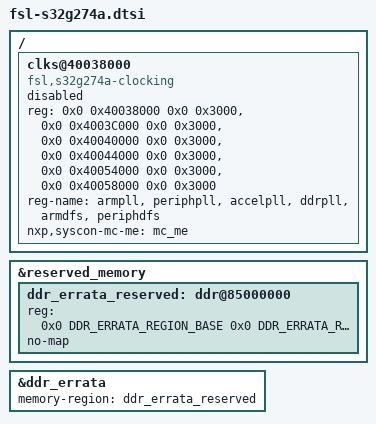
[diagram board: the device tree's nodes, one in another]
// SPDX-License-Identifier: GPL-2.0-or-later
/*
 * Device Tree file for S32G274ARDB Board.
 *
 * Copyright 2021-2022 NXP
 *
 */

#include <dt-bindings/ddr-errata/s32-ddr-errata.h>
#include "fsl-s32g.dtsi"

/ {
	clks@40038000 {
		compatible = "fsl,s32g274a-clocking";
		reg = <0x0 0x40038000 0x0 0x3000>,
		      <0x0 0x4003C000 0x0 0x3000>,
		      <0x0 0x40040000 0x0 0x3000>,
		      <0x0 0x40044000 0x0 0x3000>,
		      <0x0 0x40054000 0x0 0x3000>,
		      <0x0 0x40058000 0x0 0x3000>;
		reg-name = "armpll", "periphpll", "accelpll",
			   "ddrpll", "armdfs", "periphdfs";
		nxp,syscon-mc-me = <&mc_me>;
		#clock-cells = <1>;
		status = "disabled";
	};
};

&reserved_memory {
		ddr_errata_reserved: ddr@85000000 {
			reg = <0x0 DDR_ERRATA_REGION_BASE
				   0x0 DDR_ERRATA_REGION_SIZE>; /* 4 KB */
			no-map;
		};
};

&ddr_errata {
	memory-region = <&ddr_errata_reserved>;
	status = "okay";
};
